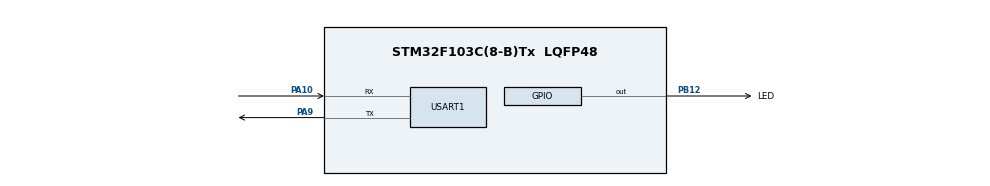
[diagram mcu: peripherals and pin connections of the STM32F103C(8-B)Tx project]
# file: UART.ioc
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Mcu.Family=STM32F1
Mcu.Name=STM32F103C(8-B)Tx
Mcu.Package=LQFP48
NVIC.PriorityGroup=NVIC_PRIORITYGROUP_4
NVIC.USART1_IRQn=true\:0\:0\:false\:false\:true\:true\:true
PA10.Mode=Asynchronous
PA10.Signal=USART1_RX
PA13.Mode=Serial_Wire
PA13.Signal=SYS_JTMS-SWDIO
PA14.Mode=Serial_Wire
PA14.Signal=SYS_JTCK-SWCLK
PA9.Mode=Asynchronous
PA9.Signal=USART1_TX
PB12.GPIO_Label=LED
PB12.Signal=GPIO_Output
PD0-OSC_IN.Mode=HSE-External-Oscillator
PD0-OSC_IN.Signal=RCC_OSC_IN
PD1-OSC_OUT.Mode=HSE-External-Oscillator
PD1-OSC_OUT.Signal=RCC_OSC_OUT
ProjectManager.HeapSize=0x200
ProjectManager.StackSize=0x400
ProjectManager.TargetToolchain=MDK-ARM V5
RCC.APB1Freq_Value=8000000
RCC.APB2Freq_Value=8000000
RCC.SYSCLKSource=RCC_SYSCLKSOURCE_HSE
USART1.VirtualMode=VM_ASYNC
board=custom

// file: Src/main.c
/* USER CODE BEGIN Header */
/**

  */
/* USER CODE END Header */

#include "main.h"
/* USER CODE BEGIN Includes */
#include "stdio.h"          // thu vien chua ham print()
#include "string.h"         // thu vien chua ham strlen()
/* USER CODE END Includes */

/* USER CODE BEGIN PV */
UART_HandleTypeDef huart1;
uint8_t Rx_count=0, Rx_reset=0,Rx_indx;
char Rx_data[5], Rx_Buffer[100];
char* str = "Hello World!\r\n";
/* USER CODE END PV */

void SystemClock_Config(void);
static void MX_GPIO_Init(void);
static void MX_USART1_UART_Init(void);
/* USER CODE BEGIN PFP */
//void HAL_UART_RxCpltCallback(UART_HandleTypeDef *huart)
//{
//	if(huart->Instance == USART1)  // kiem tra UART so may
//	{
//		//printf("hello World print\r\n");
//		if(Rx_reset=='%')                               // neu lan truoc ki tu nhan duoc la enter
//			{
//				for(int i=0; i<100; i++) Rx_Buffer[i]=0;  // reset mang
//			}
//
//		if(Rx_data[0] != 13)                           // neu ki tu nhan duoc khong phai la enter
//			{
//				 Rx_Buffer[Rx_count++] = Rx_data[0];
//				printf("khac enter\r\n");
//			}
//		else                                           // neu nhan duoc enter
//		//if(Rx_data[0] == '-')
//			{
//				if(strstr(Rx_Buffer,"BAT"))               // neu nhan chuoi ki tu "BAT"
//				{
//					HAL_GPIO_WritePin(LED_GPIO_Port, LED_Pin, GPIO_PIN_SET);       // bat led
//					HAL_UART_Transmit(&huart1, (uint8_t*) "DA BAT\r\n", 8, 100);
//				}
//				else if(strstr(Rx_Buffer,"TAT"))                                 // neu nhan chuoi ki tu "TAT"
//				{
//					HAL_GPIO_WritePin(LED_GPIO_Port, LED_Pin, GPIO_PIN_RESET);  // tat led
//					HAL_UART_Transmit(&huart1, (uint8_t*) "DA TAT\r\n", 8, 100);
//				}
//				HAL_UART_Transmit(&huart1, (uint8_t*) "Sai lenh. Xin thu lai!", 22, 100);
//				Rx_reset=0;
//				Rx_count=0;
//			}
//		HAL_UART_Receive_IT(&huart1, (uint8_t*) Rx_data, 1);
//	}
//}
void HAL_UART_RxCpltCallback(UART_HandleTypeDef *huart)
{
	if(huart->Instance == USART1)  // kiem tra UART so may
	{
		for(int i=0; i<6; i++) {Rx_Buffer[i]=Rx_data[i];Rx_data[i]=0;}
		HAL_UART_Receive_IT(&huart1, (uint8_t*) Rx_data, 3);
	}
}
/* USER CODE END PFP */

int main(void)
{
		if(strstr(Rx_Buffer,"BAT"))               // neu nhan chuoi ki tu "BAT"
			{
				HAL_GPIO_WritePin(LED_GPIO_Port, LED_Pin, GPIO_PIN_SET);       // bat led
				HAL_UART_Transmit(&huart1, (uint8_t*) "DA BAT\r\n", 8, 100);
			}
		else if(strstr(Rx_Buffer,"TAT"))                                 // neu nhan chuoi ki tu "TAT"
		{
			HAL_GPIO_WritePin(LED_GPIO_Port, LED_Pin, GPIO_PIN_RESET);  // tat led
			HAL_UART_Transmit(&huart1, (uint8_t*) "DA TAT\r\n", 8, 100);
		}
		HAL_Delay(400);

  /* MCU Configuration--------------------------------------------------------*/

  /* Reset of all peripherals, Initializes the Flash interface and the Systick. */
  HAL_Init();

  /* Configure the system clock */
  SystemClock_Config();

  /* Initialize all configured peripherals */
  MX_GPIO_Init();
  MX_USART1_UART_Init();
  /* USER CODE BEGIN 2 */
	HAL_UART_Receive_IT(&huart1, (uint8_t*) Rx_data, 5);
  /* USER CODE END 2 */

  /* Infinite loop */
  /* USER CODE BEGIN WHILE */
  while (1)
  {
		// cach 1 truyen bang lenh cua thu vien HAL
//		HAL_UART_Transmit(&huart1, (uint8_t *) str, strlen(str) ,100);    // strlen(str) tra ve gia tri so ki tu cua chuoi
		// cach 2 truyen bang ham print
//		printf("hello World print\r\n");
		HAL_Delay(1000);
    /* USER CODE END WHILE */

  }
}

void SystemClock_Config(void)
{
  RCC_OscInitTypeDef RCC_OscInitStruct = {0};
  RCC_ClkInitTypeDef RCC_ClkInitStruct = {0};

  /** Initializes the CPU, AHB and APB busses clocks
  */
  RCC_OscInitStruct.OscillatorType = RCC_OSCILLATORTYPE_HSE;
  RCC_OscInitStruct.HSEState = RCC_HSE_ON;
  RCC_OscInitStruct.PLL.PLLState = RCC_PLL_NONE;
  if (HAL_RCC_OscConfig(&RCC_OscInitStruct) != HAL_OK)
  {
    Error_Handler();
  }
  /** Initializes the CPU, AHB and APB busses clocks
  */
  RCC_ClkInitStruct.ClockType = RCC_CLOCKTYPE_HCLK|RCC_CLOCKTYPE_SYSCLK
                              |RCC_CLOCKTYPE_PCLK1|RCC_CLOCKTYPE_PCLK2;
  RCC_ClkInitStruct.SYSCLKSource = RCC_SYSCLKSOURCE_HSE;
  RCC_ClkInitStruct.AHBCLKDivider = RCC_SYSCLK_DIV1;
  RCC_ClkInitStruct.APB1CLKDivider = RCC_HCLK_DIV1;
  RCC_ClkInitStruct.APB2CLKDivider = RCC_HCLK_DIV1;

  if (HAL_RCC_ClockConfig(&RCC_ClkInitStruct, FLASH_LATENCY_0) != HAL_OK)
  {
    Error_Handler();
  }
}

static void MX_USART1_UART_Init(void)
{

  huart1.Instance = USART1;
  huart1.Init.BaudRate = 115200;
  huart1.Init.WordLength = UART_WORDLENGTH_8B;
  huart1.Init.StopBits = UART_STOPBITS_1;
  huart1.Init.Parity = UART_PARITY_NONE;
  huart1.Init.Mode = UART_MODE_TX_RX;
  huart1.Init.HwFlowCtl = UART_HWCONTROL_NONE;
  huart1.Init.OverSampling = UART_OVERSAMPLING_16;
  if (HAL_UART_Init(&huart1) != HAL_OK)
  {
    Error_Handler();
  }

}

static void MX_GPIO_Init(void)
{
  GPIO_InitTypeDef GPIO_InitStruct = {0};

  /* GPIO Ports Clock Enable */
  __HAL_RCC_GPIOD_CLK_ENABLE();
  __HAL_RCC_GPIOB_CLK_ENABLE();
  __HAL_RCC_GPIOA_CLK_ENABLE();

  /*Configure GPIO pin Output Level */
  HAL_GPIO_WritePin(LED_GPIO_Port, LED_Pin, GPIO_PIN_RESET);

  /*Configure GPIO pin : LED_Pin */
  GPIO_InitStruct.Pin = LED_Pin;
  GPIO_InitStruct.Mode = GPIO_MODE_OUTPUT_PP;
  GPIO_InitStruct.Pull = GPIO_NOPULL;
  GPIO_InitStruct.Speed = GPIO_SPEED_FREQ_LOW;
  HAL_GPIO_Init(LED_GPIO_Port, &GPIO_InitStruct);

}

/* USER CODE BEGIN 4 */
//--------------------------- add thêm doan nay vao neu dùng cách 2--------------------//
_ARMABI int fputc(int c, FILE * stream)
 {   HAL_UART_Transmit(&huart1,(uint8_t *) &c,1,100);
	 return 0;
 }
/* USER CODE END 4 */

void Error_Handler(void)
{
}

/************************ (C) COPYRIGHT STMicroelectronics *****END OF FILE****/
